# BlockA: IP-XACT component
VLNV example.vendor:example_lib:BlockA:1.0

## Bus interfaces (logical=physical port)
register_if: slave example.vendor:example_lib:register_bus:1.0, memory map BlockA_map

## Address spaces and blocks
BlockA_map.BlockA_regs: base 0x0, range 0x100, width 32, register

## Registers
Registers are 32-bit, access per field, no defined reset value unless marked. A register's access mark holds for its fields unless they carry their own. Offsets are from the block's base; lines under a group give offsets from that group; [hi:lo] are bit positions; {n}, {i} and the like mark numbered series; 'fields as' and 'values as' point back to an identical list; <NAME> marks a mode.

## BlockA_map.BlockA_regs
Base 0x00000000
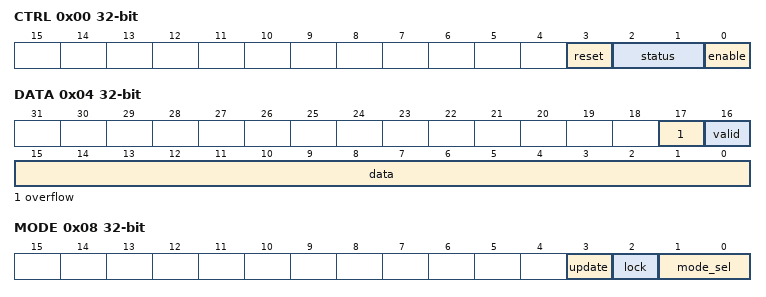
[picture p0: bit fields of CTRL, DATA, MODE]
0x00 CTRL
  [3] reset wo, [2:1] status ro, [0] enable rw
0x04 DATA
  [17] overflow rw, [16] valid ro, [15:0] data wo
0x08 MODE
  [3] update wo, [2] lock ro, [1:0] mode_sel rw
